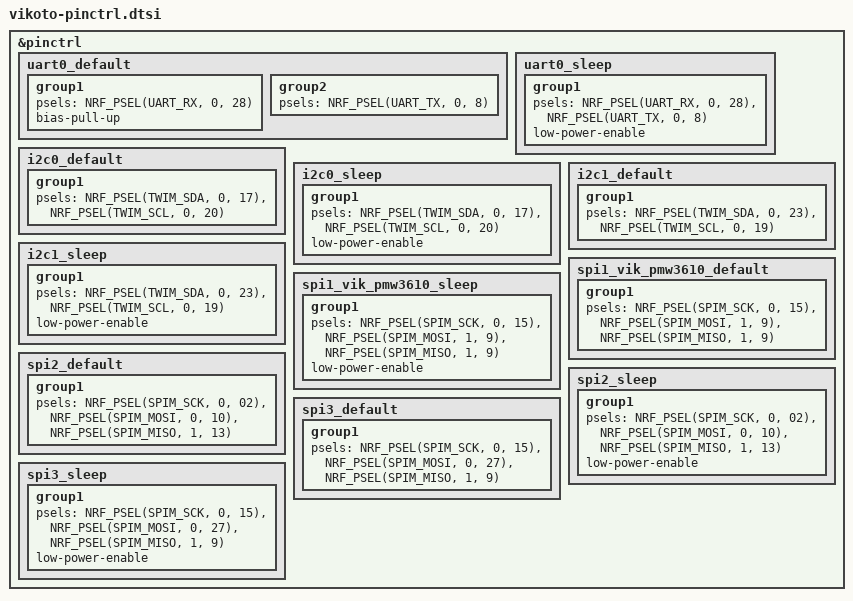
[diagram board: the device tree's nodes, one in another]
&pinctrl {
    uart0_default: uart0_default {
        group1 { psels = <NRF_PSEL(UART_RX, 0, 28)>; bias-pull-up; };
        group2 { psels = <NRF_PSEL(UART_TX, 0, 8)>; };
    };
    uart0_sleep: uart0_sleep {
        group1 { psels = <NRF_PSEL(UART_RX, 0, 28)>, <NRF_PSEL(UART_TX, 0, 8)>; low-power-enable; };
    };

    /* pro_micro I2C (i2c0) */
    i2c0_default: i2c0_default {
        group1 { psels = <NRF_PSEL(TWIM_SDA, 0, 17)>, <NRF_PSEL(TWIM_SCL, 0, 20)>; };
    };
    i2c0_sleep: i2c0_sleep {
        group1 { psels = <NRF_PSEL(TWIM_SDA, 0, 17)>, <NRF_PSEL(TWIM_SCL, 0, 20)>; low-power-enable; };
    };

    /* VIK I2C (i2c1) */
    i2c1_default: i2c1_default {
        group1 { psels = <NRF_PSEL(TWIM_SDA, 0, 23)>, <NRF_PSEL(TWIM_SCL, 0, 19)>; };
    };
    i2c1_sleep: i2c1_sleep {
        group1 { psels = <NRF_PSEL(TWIM_SDA, 0, 23)>, <NRF_PSEL(TWIM_SCL, 0, 19)>; low-power-enable; };
    };

    /* VIK PMW3610 half-duplex SPI (spi1) */
    spi1_vik_pmw3610_default: spi1_vik_pmw3610_default {
        group1 { psels = <NRF_PSEL(SPIM_SCK, 0, 15)>, <NRF_PSEL(SPIM_MOSI, 1, 9)>, <NRF_PSEL(SPIM_MISO, 1, 9)>; };
    };
    spi1_vik_pmw3610_sleep: spi1_vik_pmw3610_sleep {
        group1 { psels = <NRF_PSEL(SPIM_SCK, 0, 15)>, <NRF_PSEL(SPIM_MOSI, 1, 9)>, <NRF_PSEL(SPIM_MISO, 1, 9)>; low-power-enable; };
    };

    /* pro_micro SPI (spi2) */
    spi2_default: spi2_default {
        group1 { psels = <NRF_PSEL(SPIM_SCK, 0, 02)>, <NRF_PSEL(SPIM_MOSI, 0, 10)>, <NRF_PSEL(SPIM_MISO, 1, 13)>; };
    };
    spi2_sleep: spi2_sleep {
        group1 { psels = <NRF_PSEL(SPIM_SCK, 0, 02)>, <NRF_PSEL(SPIM_MOSI, 0, 10)>, <NRF_PSEL(SPIM_MISO, 1, 13)>; low-power-enable; };
    };

    /* VIK SPI (spi3) */
    spi3_default: spi3_default {
        group1 { psels = <NRF_PSEL(SPIM_SCK, 0, 15)>, <NRF_PSEL(SPIM_MOSI, 0, 27)>, <NRF_PSEL(SPIM_MISO, 1, 9)>; };
    };
    spi3_sleep: spi3_sleep {
        group1 { psels = <NRF_PSEL(SPIM_SCK, 0, 15)>, <NRF_PSEL(SPIM_MOSI, 0, 27)>, <NRF_PSEL(SPIM_MISO, 1, 9)>; low-power-enable; };
    };
};
